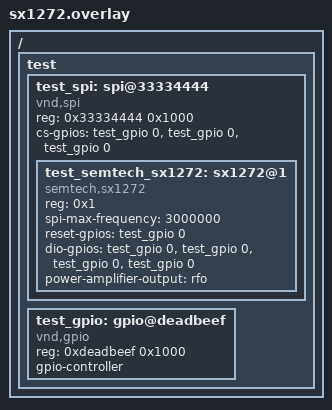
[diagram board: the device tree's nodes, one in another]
/*
 * Copyright (c) 2024 TOKITA Hiroshi
 * SPDX-License-Identifier: Apache-2.0
 */

/ {
	test {
		#address-cells = <1>;
		#size-cells = <1>;

		test_spi: spi@33334444 {
			compatible = "vnd,spi";
			reg = <0x33334444 0x1000>;
			#address-cells = <1>;
			#size-cells = <0>;

			cs-gpios = <&test_gpio 0 0>,
				   <&test_gpio 0 0>,
				   <&test_gpio 0 0>;
			status = "okay";

			test_semtech_sx1272: sx1272@1 {
				compatible = "semtech,sx1272";
				reg = <0x1>;
				spi-max-frequency = <3000000>;

				reset-gpios = <&test_gpio 0 0>;

				dio-gpios = <&test_gpio 0 0>,
					    <&test_gpio 0 0>,
					    <&test_gpio 0 0>,
					    <&test_gpio 0 0>;

				power-amplifier-output = "rfo";
				status = "okay";
			};
		};

		test_gpio: gpio@deadbeef {
			compatible = "vnd,gpio";
			reg = <0xdeadbeef 0x1000>;
			gpio-controller;
			#gpio-cells = <0x2>;
			status = "okay";
		};
	};
};
